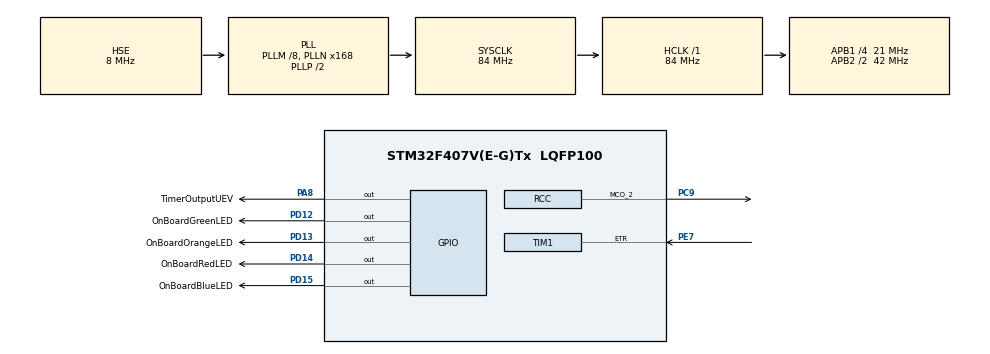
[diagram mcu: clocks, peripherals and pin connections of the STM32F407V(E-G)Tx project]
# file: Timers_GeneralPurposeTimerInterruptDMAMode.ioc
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Dma.Request0=TIM1_UP
Dma.TIM1_UP.0.Direction=DMA_MEMORY_TO_PERIPH
Dma.TIM1_UP.0.FIFOMode=DMA_FIFOMODE_DISABLE
Dma.TIM1_UP.0.Instance=DMA2_Stream5
Dma.TIM1_UP.0.MemDataAlignment=DMA_MDATAALIGN_HALFWORD
Dma.TIM1_UP.0.MemInc=DMA_MINC_ENABLE
Dma.TIM1_UP.0.Mode=DMA_CIRCULAR
Dma.TIM1_UP.0.PeriphDataAlignment=DMA_PDATAALIGN_HALFWORD
Dma.TIM1_UP.0.PeriphInc=DMA_PINC_DISABLE
Dma.TIM1_UP.0.Priority=DMA_PRIORITY_LOW
Mcu.Family=STM32F4
Mcu.Name=STM32F407V(E-G)Tx
Mcu.Package=LQFP100
NVIC.DMA2_Stream5_IRQn=true\:0\:0\:false\:false\:true\:false\:true
NVIC.PriorityGroup=NVIC_PRIORITYGROUP_0
NVIC.TIM1_UP_TIM10_IRQn=true\:0\:0\:false\:false\:true\:true\:true
PA10.GPIO_Label=OTG_FS_ID
PA10.GPIO_Mode=GPIO_MODE_AF_PP
PA10.GPIO_PuPd=GPIO_NOPULL
PA10.GPIO_Speed=GPIO_SPEED_FREQ_LOW
PA10.Signal=USB_OTG_FS_ID
PA11.GPIO_Label=OTG_FS_DM
PA11.GPIO_Mode=GPIO_MODE_AF_PP
PA11.GPIO_PuPd=GPIO_NOPULL
PA11.GPIO_Speed=GPIO_SPEED_FREQ_LOW
PA11.Signal=USB_OTG_FS_DM
PA12.GPIO_Label=OTG_FS_DP
PA12.GPIO_Mode=GPIO_MODE_AF_PP
PA12.GPIO_PuPd=GPIO_NOPULL
PA12.GPIO_Speed=GPIO_SPEED_FREQ_LOW
PA12.Signal=USB_OTG_FS_DP
PA13.GPIO_Label=SWDIO
PA13.Signal=SYS_JTMS-SWDIO
PA14.GPIO_Label=SWCLK
PA14.Signal=SYS_JTCK-SWCLK
PA4.GPIO_Label=I2S3_WS [CS43L22_LRCK]
PA4.GPIO_Mode=GPIO_MODE_AF_PP
PA4.GPIO_PuPd=GPIO_NOPULL
PA4.GPIO_Speed=GPIO_SPEED_FREQ_LOW
PA4.Signal=I2S3_WS
PA5.GPIO_Label=SPI1_SCK [LIS302DL_SCL/SPC]
PA5.GPIO_Mode=GPIO_MODE_AF_PP
PA5.GPIO_PuPd=GPIO_NOPULL
PA5.GPIO_Speed=GPIO_SPEED_FREQ_LOW
PA5.Signal=SPI1_SCK
PA6.GPIO_Label=SPI1_MISO [LIS302DL_SDO]
PA6.GPIO_Mode=GPIO_MODE_AF_PP
PA6.GPIO_PuPd=GPIO_NOPULL
PA6.GPIO_Speed=GPIO_SPEED_FREQ_LOW
PA6.Signal=SPI1_MISO
PA7.GPIO_Label=SPI1_MOSI [LIS302DL_SDA/SDI/SDO]
PA7.GPIO_Mode=GPIO_MODE_AF_PP
PA7.GPIO_PuPd=GPIO_NOPULL
PA7.GPIO_Speed=GPIO_SPEED_FREQ_LOW
PA7.Signal=SPI1_MOSI
PA8.GPIO_Label=TimerOutputUEV
PA8.GPIO_Speed=GPIO_SPEED_FREQ_VERY_HIGH
PA8.Signal=GPIO_Output
PA9.GPIO_Label=VBUS_FS
PA9.GPIO_Mode=GPIO_MODE_INPUT
PA9.GPIO_PuPd=GPIO_NOPULL
PA9.Signal=USB_OTG_FS_VBUS
PB10.GPIO_Label=CLK_IN [MP45DT02_CLK]
PB10.GPIO_Mode=GPIO_MODE_AF_PP
PB10.GPIO_PuPd=GPIO_NOPULL
PB10.GPIO_Speed=GPIO_SPEED_FREQ_LOW
PB10.Signal=I2S2_CK
PB3.GPIO_Label=SWO
PB3.Signal=SYS_JTDO-SWO
PB6.GPIO_Label=Audio_SCL [CS43L22_SCL]
PB6.GPIO_Mode=GPIO_MODE_AF_OD
PB6.GPIO_PuPd=GPIO_NOPULL
PB6.GPIO_Speed=GPIO_SPEED_FREQ_LOW
PB6.Signal=I2C1_SCL
PB9.GPIO_Label=Audio_SDA [CS43L22_SDA]
PB9.GPIO_Mode=GPIO_MODE_AF_OD
PB9.GPIO_PuPd=GPIO_NOPULL
PB9.GPIO_Speed=GPIO_SPEED_FREQ_LOW
PB9.Signal=I2C1_SDA
PC10.GPIO_Label=I2S3_SCK [CS43L22_SCLK]
PC10.GPIO_Mode=GPIO_MODE_AF_PP
PC10.GPIO_PuPd=GPIO_NOPULL
PC10.GPIO_Speed=GPIO_SPEED_FREQ_LOW
PC10.Signal=I2S3_CK
PC12.GPIO_Label=I2S3_SD [CS43L22_SDIN]
PC12.GPIO_Mode=GPIO_MODE_AF_PP
PC12.GPIO_PuPd=GPIO_NOPULL
PC12.GPIO_Speed=GPIO_SPEED_FREQ_LOW
PC12.Signal=I2S3_SD
PC14-OSC32_IN.GPIO_Label=PC14-OSC32_IN
PC14-OSC32_IN.Signal=RCC_OSC32_IN
PC15-OSC32_OUT.GPIO_Label=PC15-OSC32_OUT
PC15-OSC32_OUT.Signal=RCC_OSC32_OUT
PC3.GPIO_Label=PDM_OUT [MP45DT02_DOUT]
PC3.GPIO_Mode=GPIO_MODE_AF_PP
PC3.GPIO_PuPd=GPIO_NOPULL
PC3.GPIO_Speed=GPIO_SPEED_FREQ_LOW
PC3.Signal=I2S2_SD
PC7.GPIO_Label=I2S3_MCK [CS43L22_MCLK]
PC7.GPIO_Mode=GPIO_MODE_AF_PP
PC7.GPIO_PuPd=GPIO_NOPULL
PC7.GPIO_Speed=GPIO_SPEED_FREQ_LOW
PC7.Signal=I2S3_MCK
PC9.Mode=Clock-out-2
PC9.Signal=RCC_MCO_2
PD12.GPIO_Label=OnBoardGreenLED
PD12.Signal=GPIO_Output
PD13.GPIO_Label=OnBoardOrangeLED
PD13.Signal=GPIO_Output
PD14.GPIO_Label=OnBoardRedLED
PD14.Signal=GPIO_Output
PD15.GPIO_Label=OnBoardBlueLED
PD15.Signal=GPIO_Output
PE7.Signal=S_TIM1_ETR
PH0-OSC_IN.GPIO_Label=PH0-OSC_IN
PH0-OSC_IN.Mode=HSE-External-Oscillator
PH0-OSC_IN.Signal=RCC_OSC_IN
PH1-OSC_OUT.GPIO_Label=PH1-OSC_OUT
PH1-OSC_OUT.Mode=HSE-External-Oscillator
PH1-OSC_OUT.Signal=RCC_OSC_OUT
ProjectManager.HeapSize=0x200
ProjectManager.StackSize=0x400
ProjectManager.TargetToolchain=STM32CubeIDE
RCC.48MHZClocksFreq_Value=24000000
RCC.AHBFreq_Value=84000000
RCC.APB1CLKDivider=RCC_HCLK_DIV4
RCC.APB1Freq_Value=21000000
RCC.APB1TimFreq_Value=42000000
RCC.APB2CLKDivider=RCC_HCLK_DIV2
RCC.APB2Freq_Value=42000000
RCC.APB2TimFreq_Value=84000000
RCC.CortexFreq_Value=84000000
RCC.HCLKFreq_Value=84000000
RCC.HSE_VALUE=8000000
RCC.HSI_VALUE=16000000
RCC.LSE_VALUE=32768
RCC.PLLM=8
RCC.PLLN=168
RCC.PLLQ=7
RCC.PLLSourceVirtual=RCC_PLLSOURCE_HSE
RCC.RCC_MCO2Source=RCC_MCO2SOURCE_HSE
RCC.SYSCLKFreq_VALUE=84000000
RCC.SYSCLKSource=RCC_SYSCLKSOURCE_PLLCLK
RCC.VCOOutputFreq_Value=168000000
SH.S_TIM1_ETR.0=TIM1_ETR,ClockSourceETR_Mode2
TIM1.ClockDivision=TIM_CLOCKDIVISION_DIV1
TIM1.ClockPrescaler=TIM_CLOCKPRESCALER_DIV4
TIM1.Period=499
TIM1.Prescaler=999
TIM1.RepetitionCounter=1
TIM1.TIM_MasterOutputTrigger=TIM_TRGO_UPDATE
board=STM32F407G-DISC1

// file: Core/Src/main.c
/* USER CODE BEGIN Header */
/**
  ******************************************************************************
  * @file           : main.c
  * @brief          : Main program body
  ******************************************************************************
  * @attention
  *
  * <h2><center>&copy; Copyright (c) 2020 STMicroelectronics.
  * All rights reserved.</center></h2>
  *
  * This software component is licensed by ST under BSD 3-Clause license,
  * the "License"; You may not use this file except in compliance with the
  * License. You may obtain a copy of the License at:
  *                        opensource.org/licenses/BSD-3-Clause
  *
  ******************************************************************************
  */
/* USER CODE END Header */

#include "main.h"

TIM_HandleTypeDef htim1;
DMA_HandleTypeDef hdma_tim1_up;

/* USER CODE BEGIN PV */
uint8_t counter = 0;
uint16_t led_data[] = {0x8000, 0x0000, 0xC000, 0x0000, 0xE000, 0x0000, 0xF000, 0x0000, };
/* USER CODE END PV */

void SystemClock_Config(void);
static void MX_GPIO_Init(void);
static void MX_DMA_Init(void);
static void MX_TIM1_Init(void);

int main(void)
{

  /* MCU Configuration--------------------------------------------------------*/

  /* Reset of all peripherals, Initializes the Flash interface and the Systick. */
  HAL_Init();

  /* Configure the system clock */
  SystemClock_Config();

  /* Initialize all configured peripherals */
  MX_GPIO_Init();
  MX_DMA_Init();
  MX_TIM1_Init();
  /* USER CODE BEGIN 2 */
  HAL_TIM_Base_Start_IT(&htim1);
  HAL_DMA_Start_IT(&hdma_tim1_up, (uint32_t)led_data, (uint32_t)&GPIOD->ODR, 8);
  __HAL_TIM_ENABLE_DMA(&htim1, TIM_DMA_UPDATE);
  /* USER CODE END 2 */

  /* Infinite loop */
  while (1)
  {

  }
}

void SystemClock_Config(void)
{
  RCC_OscInitTypeDef RCC_OscInitStruct = {0};
  RCC_ClkInitTypeDef RCC_ClkInitStruct = {0};

  /** Configure the main internal regulator output voltage
  */
  __HAL_RCC_PWR_CLK_ENABLE();
  __HAL_PWR_VOLTAGESCALING_CONFIG(PWR_REGULATOR_VOLTAGE_SCALE1);
  /** Initializes the CPU, AHB and APB busses clocks
  */
  RCC_OscInitStruct.OscillatorType = RCC_OSCILLATORTYPE_HSE;
  RCC_OscInitStruct.HSEState = RCC_HSE_ON;
  RCC_OscInitStruct.PLL.PLLState = RCC_PLL_ON;
  RCC_OscInitStruct.PLL.PLLSource = RCC_PLLSOURCE_HSE;
  RCC_OscInitStruct.PLL.PLLM = 8;
  RCC_OscInitStruct.PLL.PLLN = 168;
  RCC_OscInitStruct.PLL.PLLP = RCC_PLLP_DIV2;
  RCC_OscInitStruct.PLL.PLLQ = 7;
  if (HAL_RCC_OscConfig(&RCC_OscInitStruct) != HAL_OK)
  {
    Error_Handler();
  }
  /** Initializes the CPU, AHB and APB busses clocks
  */
  RCC_ClkInitStruct.ClockType = RCC_CLOCKTYPE_HCLK|RCC_CLOCKTYPE_SYSCLK
                              |RCC_CLOCKTYPE_PCLK1|RCC_CLOCKTYPE_PCLK2;
  RCC_ClkInitStruct.SYSCLKSource = RCC_SYSCLKSOURCE_PLLCLK;
  RCC_ClkInitStruct.AHBCLKDivider = RCC_SYSCLK_DIV1;
  RCC_ClkInitStruct.APB1CLKDivider = RCC_HCLK_DIV4;
  RCC_ClkInitStruct.APB2CLKDivider = RCC_HCLK_DIV2;

  if (HAL_RCC_ClockConfig(&RCC_ClkInitStruct, FLASH_LATENCY_2) != HAL_OK)
  {
    Error_Handler();
  }
  HAL_RCC_MCOConfig(RCC_MCO2, RCC_MCO2SOURCE_HSE, RCC_MCODIV_1);
}

static void MX_TIM1_Init(void)
{

  TIM_ClockConfigTypeDef sClockSourceConfig = {0};
  TIM_MasterConfigTypeDef sMasterConfig = {0};

  htim1.Instance = TIM1;
  htim1.Init.Prescaler = 999;
  htim1.Init.CounterMode = TIM_COUNTERMODE_UP;
  htim1.Init.Period = 499;
  htim1.Init.ClockDivision = TIM_CLOCKDIVISION_DIV1;
  htim1.Init.RepetitionCounter = 1;
  htim1.Init.AutoReloadPreload = TIM_AUTORELOAD_PRELOAD_DISABLE;
  if (HAL_TIM_Base_Init(&htim1) != HAL_OK)
  {
    Error_Handler();
  }
  sClockSourceConfig.ClockSource = TIM_CLOCKSOURCE_ETRMODE2;
  sClockSourceConfig.ClockPolarity = TIM_CLOCKPOLARITY_NONINVERTED;
  sClockSourceConfig.ClockPrescaler = TIM_CLOCKPRESCALER_DIV4;
  sClockSourceConfig.ClockFilter = 0;
  if (HAL_TIM_ConfigClockSource(&htim1, &sClockSourceConfig) != HAL_OK)
  {
    Error_Handler();
  }
  sMasterConfig.MasterOutputTrigger = TIM_TRGO_UPDATE;
  sMasterConfig.MasterSlaveMode = TIM_MASTERSLAVEMODE_DISABLE;
  if (HAL_TIMEx_MasterConfigSynchronization(&htim1, &sMasterConfig) != HAL_OK)
  {
    Error_Handler();
  }

}

static void MX_DMA_Init(void)
{

  /* DMA controller clock enable */
  __HAL_RCC_DMA2_CLK_ENABLE();

  /* DMA interrupt init */
  /* DMA2_Stream5_IRQn interrupt configuration */
  HAL_NVIC_SetPriority(DMA2_Stream5_IRQn, 0, 0);
  HAL_NVIC_EnableIRQ(DMA2_Stream5_IRQn);

}

static void MX_GPIO_Init(void)
{
  GPIO_InitTypeDef GPIO_InitStruct = {0};

  /* GPIO Ports Clock Enable */
  __HAL_RCC_GPIOC_CLK_ENABLE();
  __HAL_RCC_GPIOH_CLK_ENABLE();
  __HAL_RCC_GPIOA_CLK_ENABLE();
  __HAL_RCC_GPIOE_CLK_ENABLE();
  __HAL_RCC_GPIOB_CLK_ENABLE();
  __HAL_RCC_GPIOD_CLK_ENABLE();

  /*Configure GPIO pin Output Level */
  HAL_GPIO_WritePin(GPIOD, OnBoardGreenLED_Pin|OnBoardOrangeLED_Pin|OnBoardRedLED_Pin|OnBoardBlueLED_Pin, GPIO_PIN_RESET);

  /*Configure GPIO pin Output Level */
  HAL_GPIO_WritePin(TimerOutputUEV_GPIO_Port, TimerOutputUEV_Pin, GPIO_PIN_RESET);

  /*Configure GPIO pin : PDM_OUT_Pin */
  GPIO_InitStruct.Pin = PDM_OUT_Pin;
  GPIO_InitStruct.Mode = GPIO_MODE_AF_PP;
  GPIO_InitStruct.Pull = GPIO_NOPULL;
  GPIO_InitStruct.Speed = GPIO_SPEED_FREQ_LOW;
  GPIO_InitStruct.Alternate = GPIO_AF5_SPI2;
  HAL_GPIO_Init(PDM_OUT_GPIO_Port, &GPIO_InitStruct);

  /*Configure GPIO pin : I2S3_WS_Pin */
  GPIO_InitStruct.Pin = I2S3_WS_Pin;
  GPIO_InitStruct.Mode = GPIO_MODE_AF_PP;
  GPIO_InitStruct.Pull = GPIO_NOPULL;
  GPIO_InitStruct.Speed = GPIO_SPEED_FREQ_LOW;
  GPIO_InitStruct.Alternate = GPIO_AF6_SPI3;
  HAL_GPIO_Init(I2S3_WS_GPIO_Port, &GPIO_InitStruct);

  /*Configure GPIO pins : SPI1_SCK_Pin SPI1_MISO_Pin SPI1_MOSI_Pin */
  GPIO_InitStruct.Pin = SPI1_SCK_Pin|SPI1_MISO_Pin|SPI1_MOSI_Pin;
  GPIO_InitStruct.Mode = GPIO_MODE_AF_PP;
  GPIO_InitStruct.Pull = GPIO_NOPULL;
  GPIO_InitStruct.Speed = GPIO_SPEED_FREQ_LOW;
  GPIO_InitStruct.Alternate = GPIO_AF5_SPI1;
  HAL_GPIO_Init(GPIOA, &GPIO_InitStruct);

  /*Configure GPIO pin : CLK_IN_Pin */
  GPIO_InitStruct.Pin = CLK_IN_Pin;
  GPIO_InitStruct.Mode = GPIO_MODE_AF_PP;
  GPIO_InitStruct.Pull = GPIO_NOPULL;
  GPIO_InitStruct.Speed = GPIO_SPEED_FREQ_LOW;
  GPIO_InitStruct.Alternate = GPIO_AF5_SPI2;
  HAL_GPIO_Init(CLK_IN_GPIO_Port, &GPIO_InitStruct);

  /*Configure GPIO pins : OnBoardGreenLED_Pin OnBoardOrangeLED_Pin OnBoardRedLED_Pin OnBoardBlueLED_Pin */
  GPIO_InitStruct.Pin = OnBoardGreenLED_Pin|OnBoardOrangeLED_Pin|OnBoardRedLED_Pin|OnBoardBlueLED_Pin;
  GPIO_InitStruct.Mode = GPIO_MODE_OUTPUT_PP;
  GPIO_InitStruct.Pull = GPIO_NOPULL;
  GPIO_InitStruct.Speed = GPIO_SPEED_FREQ_LOW;
  HAL_GPIO_Init(GPIOD, &GPIO_InitStruct);

  /*Configure GPIO pins : I2S3_MCK_Pin I2S3_SCK_Pin I2S3_SD_Pin */
  GPIO_InitStruct.Pin = I2S3_MCK_Pin|I2S3_SCK_Pin|I2S3_SD_Pin;
  GPIO_InitStruct.Mode = GPIO_MODE_AF_PP;
  GPIO_InitStruct.Pull = GPIO_NOPULL;
  GPIO_InitStruct.Speed = GPIO_SPEED_FREQ_LOW;
  GPIO_InitStruct.Alternate = GPIO_AF6_SPI3;
  HAL_GPIO_Init(GPIOC, &GPIO_InitStruct);

  /*Configure GPIO pin : PC9 */
  GPIO_InitStruct.Pin = GPIO_PIN_9;
  GPIO_InitStruct.Mode = GPIO_MODE_AF_PP;
  GPIO_InitStruct.Pull = GPIO_NOPULL;
  GPIO_InitStruct.Speed = GPIO_SPEED_FREQ_LOW;
  GPIO_InitStruct.Alternate = GPIO_AF0_MCO;
  HAL_GPIO_Init(GPIOC, &GPIO_InitStruct);

  /*Configure GPIO pin : TimerOutputUEV_Pin */
  GPIO_InitStruct.Pin = TimerOutputUEV_Pin;
  GPIO_InitStruct.Mode = GPIO_MODE_OUTPUT_PP;
  GPIO_InitStruct.Pull = GPIO_NOPULL;
  GPIO_InitStruct.Speed = GPIO_SPEED_FREQ_VERY_HIGH;
  HAL_GPIO_Init(TimerOutputUEV_GPIO_Port, &GPIO_InitStruct);

  /*Configure GPIO pin : VBUS_FS_Pin */
  GPIO_InitStruct.Pin = VBUS_FS_Pin;
  GPIO_InitStruct.Mode = GPIO_MODE_INPUT;
  GPIO_InitStruct.Pull = GPIO_NOPULL;
  HAL_GPIO_Init(VBUS_FS_GPIO_Port, &GPIO_InitStruct);

  /*Configure GPIO pins : OTG_FS_ID_Pin OTG_FS_DM_Pin OTG_FS_DP_Pin */
  GPIO_InitStruct.Pin = OTG_FS_ID_Pin|OTG_FS_DM_Pin|OTG_FS_DP_Pin;
  GPIO_InitStruct.Mode = GPIO_MODE_AF_PP;
  GPIO_InitStruct.Pull = GPIO_NOPULL;
  GPIO_InitStruct.Speed = GPIO_SPEED_FREQ_LOW;
  GPIO_InitStruct.Alternate = GPIO_AF10_OTG_FS;
  HAL_GPIO_Init(GPIOA, &GPIO_InitStruct);

  /*Configure GPIO pins : Audio_SCL_Pin Audio_SDA_Pin */
  GPIO_InitStruct.Pin = Audio_SCL_Pin|Audio_SDA_Pin;
  GPIO_InitStruct.Mode = GPIO_MODE_AF_OD;
  GPIO_InitStruct.Pull = GPIO_PULLUP;
  GPIO_InitStruct.Speed = GPIO_SPEED_FREQ_LOW;
  GPIO_InitStruct.Alternate = GPIO_AF4_I2C1;
  HAL_GPIO_Init(GPIOB, &GPIO_InitStruct);

}

/* USER CODE BEGIN 4 */
void HAL_TIM_PeriodElapsedCallback(TIM_HandleTypeDef *htim) {
	counter++;
	HAL_GPIO_TogglePin(TimerOutputUEV_GPIO_Port, TimerOutputUEV_Pin);
}
/* USER CODE END 4 */

void Error_Handler(void)
{
}

/************************ (C) COPYRIGHT STMicroelectronics *****END OF FILE****/
